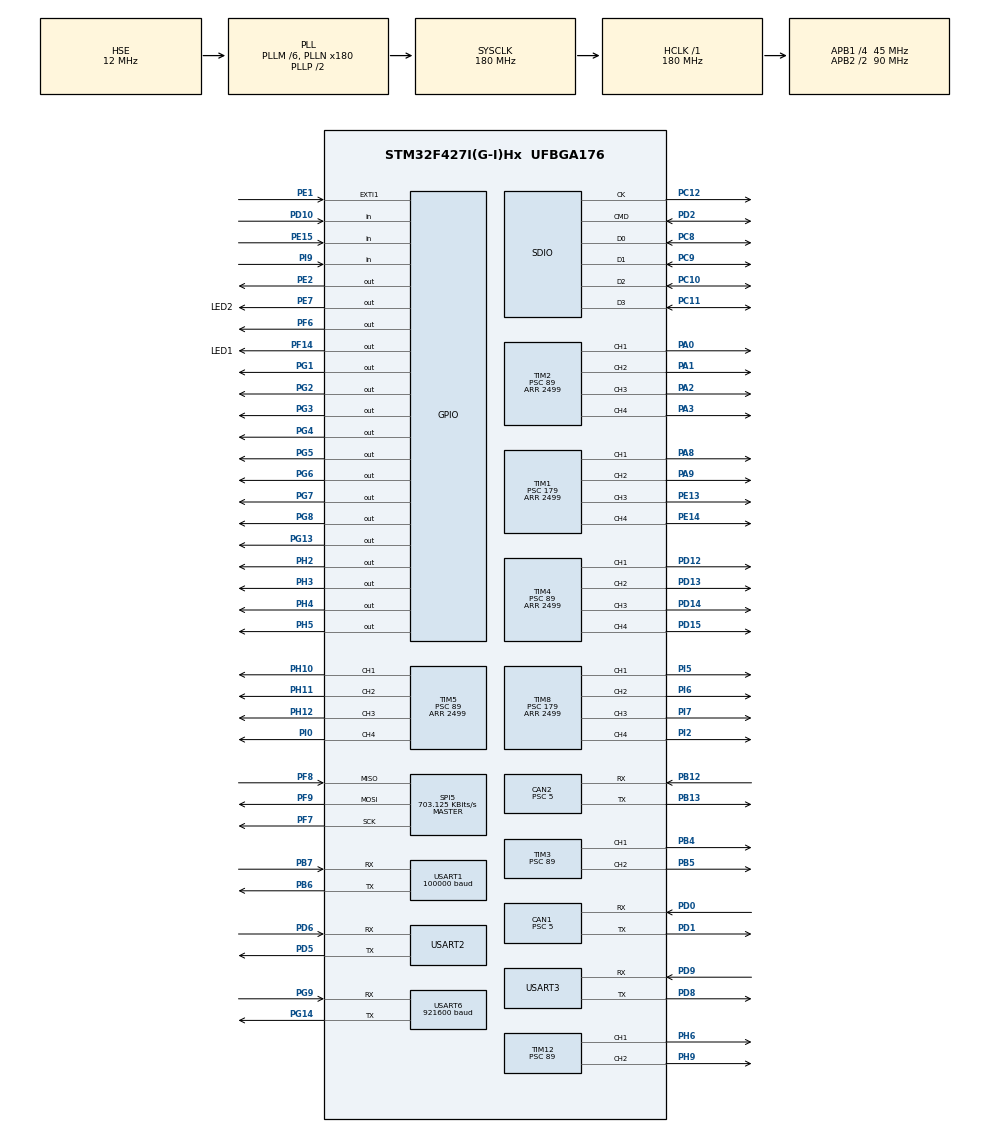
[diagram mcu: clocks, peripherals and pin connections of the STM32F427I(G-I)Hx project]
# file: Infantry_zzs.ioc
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CAN1.ABOM=ENABLE
CAN1.BS1=CAN_BS1_3TQ
CAN1.BS2=CAN_BS2_5TQ
CAN1.CalculateTimeQuantum=111.11111111111111
CAN1.Prescaler=5
CAN2.ABOM=ENABLE
CAN2.BS1=CAN_BS1_3TQ
CAN2.BS2=CAN_BS2_5TQ
CAN2.CalculateTimeQuantum=111.11111111111111
CAN2.Prescaler=5
CAN2.SJW=CAN_SJW_4TQ
Dma.Request0=USART1_RX
Dma.Request1=USART2_RX
Dma.Request2=USART2_TX
Dma.Request3=USART3_RX
Dma.Request4=USART3_TX
Dma.Request5=USART6_RX
Dma.Request6=USART6_TX
Dma.USART1_RX.0.Direction=DMA_PERIPH_TO_MEMORY
Dma.USART1_RX.0.FIFOMode=DMA_FIFOMODE_DISABLE
Dma.USART1_RX.0.Instance=DMA2_Stream2
Dma.USART1_RX.0.MemDataAlignment=DMA_MDATAALIGN_BYTE
Dma.USART1_RX.0.MemInc=DMA_MINC_ENABLE
Dma.USART1_RX.0.Mode=DMA_NORMAL
Dma.USART1_RX.0.PeriphDataAlignment=DMA_PDATAALIGN_BYTE
Dma.USART1_RX.0.PeriphInc=DMA_PINC_DISABLE
Dma.USART1_RX.0.Priority=DMA_PRIORITY_LOW
Dma.USART2_RX.1.Direction=DMA_PERIPH_TO_MEMORY
Dma.USART2_RX.1.FIFOMode=DMA_FIFOMODE_DISABLE
Dma.USART2_RX.1.Instance=DMA1_Stream5
Dma.USART2_RX.1.MemDataAlignment=DMA_MDATAALIGN_BYTE
Dma.USART2_RX.1.MemInc=DMA_MINC_ENABLE
Dma.USART2_RX.1.Mode=DMA_NORMAL
Dma.USART2_RX.1.PeriphDataAlignment=DMA_PDATAALIGN_BYTE
Dma.USART2_RX.1.PeriphInc=DMA_PINC_DISABLE
Dma.USART2_RX.1.Priority=DMA_PRIORITY_LOW
Dma.USART2_TX.2.Direction=DMA_MEMORY_TO_PERIPH
Dma.USART2_TX.2.FIFOMode=DMA_FIFOMODE_DISABLE
Dma.USART2_TX.2.Instance=DMA1_Stream6
Dma.USART2_TX.2.MemDataAlignment=DMA_MDATAALIGN_BYTE
Dma.USART2_TX.2.MemInc=DMA_MINC_ENABLE
Dma.USART2_TX.2.Mode=DMA_NORMAL
Dma.USART2_TX.2.PeriphDataAlignment=DMA_PDATAALIGN_BYTE
Dma.USART2_TX.2.PeriphInc=DMA_PINC_DISABLE
Dma.USART2_TX.2.Priority=DMA_PRIORITY_LOW
Dma.USART3_RX.3.Direction=DMA_PERIPH_TO_MEMORY
Dma.USART3_RX.3.FIFOMode=DMA_FIFOMODE_DISABLE
Dma.USART3_RX.3.Instance=DMA1_Stream1
Dma.USART3_RX.3.MemDataAlignment=DMA_MDATAALIGN_BYTE
Dma.USART3_RX.3.MemInc=DMA_MINC_ENABLE
Dma.USART3_RX.3.Mode=DMA_NORMAL
Dma.USART3_RX.3.PeriphDataAlignment=DMA_PDATAALIGN_BYTE
Dma.USART3_RX.3.PeriphInc=DMA_PINC_DISABLE
Dma.USART3_RX.3.Priority=DMA_PRIORITY_LOW
Dma.USART3_TX.4.Direction=DMA_MEMORY_TO_PERIPH
Dma.USART3_TX.4.FIFOMode=DMA_FIFOMODE_DISABLE
Dma.USART3_TX.4.Instance=DMA1_Stream3
Dma.USART3_TX.4.MemDataAlignment=DMA_MDATAALIGN_BYTE
Dma.USART3_TX.4.MemInc=DMA_MINC_ENABLE
Dma.USART3_TX.4.Mode=DMA_NORMAL
Dma.USART3_TX.4.PeriphDataAlignment=DMA_PDATAALIGN_BYTE
Dma.USART3_TX.4.PeriphInc=DMA_PINC_DISABLE
Dma.USART3_TX.4.Priority=DMA_PRIORITY_LOW
Dma.USART6_RX.5.Direction=DMA_PERIPH_TO_MEMORY
Dma.USART6_RX.5.FIFOMode=DMA_FIFOMODE_DISABLE
Dma.USART6_RX.5.Instance=DMA2_Stream1
Dma.USART6_RX.5.MemDataAlignment=DMA_MDATAALIGN_BYTE
Dma.USART6_RX.5.MemInc=DMA_MINC_ENABLE
Dma.USART6_RX.5.Mode=DMA_NORMAL
Dma.USART6_RX.5.PeriphDataAlignment=DMA_PDATAALIGN_BYTE
Dma.USART6_RX.5.PeriphInc=DMA_PINC_DISABLE
Dma.USART6_RX.5.Priority=DMA_PRIORITY_LOW
Dma.USART6_TX.6.Direction=DMA_MEMORY_TO_PERIPH
Dma.USART6_TX.6.FIFOMode=DMA_FIFOMODE_DISABLE
Dma.USART6_TX.6.Instance=DMA2_Stream6
Dma.USART6_TX.6.MemDataAlignment=DMA_MDATAALIGN_BYTE
Dma.USART6_TX.6.MemInc=DMA_MINC_ENABLE
Dma.USART6_TX.6.Mode=DMA_NORMAL
Dma.USART6_TX.6.PeriphDataAlignment=DMA_PDATAALIGN_BYTE
Dma.USART6_TX.6.PeriphInc=DMA_PINC_DISABLE
Dma.USART6_TX.6.Priority=DMA_PRIORITY_LOW
FREERTOS.INCLUDE_pcTaskGetTaskName=0
FREERTOS.INCLUDE_uxTaskGetStackHighWaterMark=1
FREERTOS.INCLUDE_vTaskDelayUntil=1
FREERTOS.Tasks01=defaultTask,0,128,StartDefaultTask,Default,NULL,Dynamic,NULL,NULL;myTask02,3,256,StartTask02,As weak,NULL,Dynamic,NULL,NULL;myTask03,2,256,StartTask03,As weak,NULL,Dynamic,NULL,NULL;myTask04,1,256,StartTask04,As weak,NULL,Dynamic,NULL,NULL;myTask05,0,256,StartTask05,As weak,NULL,Dynamic,NULL,NULL;myTask06,-1,128,StartTask06,As weak,NULL,Dynamic,NULL,NULL;myTask07,-2,128,StartTask07,As weak,NULL,Dynamic,NULL,NULL;myTask08,-3,128,StartTask08,As weak,NULL,Dynamic,NULL,NULL
FREERTOS.configCHECK_FOR_STACK_OVERFLOW=1
FREERTOS.configTIMER_TASK_STACK_DEPTH=128
FREERTOS.configUSE_TIMERS=1
FREERTOS.configUSE_TRACE_FACILITY=1
Mcu.Family=STM32F4
Mcu.Name=STM32F427I(G-I)Hx
Mcu.Package=UFBGA176
NVIC.CAN1_RX0_IRQn=true\:5\:0\:false\:false\:true\:true\:true
NVIC.CAN1_TX_IRQn=true\:5\:0\:false\:false\:true\:true\:true
NVIC.CAN2_RX0_IRQn=true\:6\:0\:true\:false\:true\:true\:true
NVIC.CAN2_TX_IRQn=true\:6\:0\:true\:false\:true\:true\:true
NVIC.DMA1_Stream1_IRQn=true\:5\:0\:false\:false\:true\:true\:false
NVIC.DMA1_Stream3_IRQn=true\:5\:0\:false\:false\:true\:true\:false
NVIC.DMA1_Stream5_IRQn=true\:5\:0\:false\:false\:true\:true\:false
NVIC.DMA1_Stream6_IRQn=true\:5\:0\:false\:false\:true\:true\:false
NVIC.DMA2_Stream1_IRQn=true\:5\:0\:false\:false\:true\:true\:false
NVIC.DMA2_Stream2_IRQn=true\:5\:0\:false\:false\:true\:true\:false
NVIC.DMA2_Stream6_IRQn=true\:5\:0\:false\:false\:true\:true\:false
NVIC.PriorityGroup=NVIC_PRIORITYGROUP_4
NVIC.SDIO_IRQn=true\:5\:0\:false\:false\:true\:true\:true
NVIC.TIM6_DAC_IRQn=true\:0\:0\:false\:false\:true\:false\:false
NVIC.TimeBase=TIM6_DAC_IRQn
NVIC.TimeBaseIP=TIM6
NVIC.USART1_IRQn=true\:5\:0\:false\:false\:true\:true\:true
NVIC.USART2_IRQn=true\:5\:0\:false\:false\:true\:true\:true
NVIC.USART6_IRQn=true\:5\:0\:false\:false\:true\:true\:true
PA0/WKUP.Signal=S_TIM2_CH1_ETR
PA1.Signal=S_TIM2_CH2
PA13.Mode=Serial_Wire
PA13.Signal=SYS_JTMS-SWDIO
PA14.Mode=Serial_Wire
PA14.Signal=SYS_JTCK-SWCLK
PA2.Signal=S_TIM2_CH3
PA3.Signal=S_TIM2_CH4
PA8.Signal=S_TIM1_CH1
PA9.Signal=S_TIM1_CH2
PB12.Mode=Slave
PB12.Signal=CAN2_RX
PB13.Mode=Slave
PB13.Signal=CAN2_TX
PB4.Signal=S_TIM3_CH1
PB5.Signal=S_TIM3_CH2
PB6.Mode=Asynchronous
PB6.Signal=USART1_TX
PB7.Mode=Asynchronous
PB7.Signal=USART1_RX
PC10.Mode=SD_4_bits_Wide_bus
PC10.Signal=SDIO_D2
PC11.Mode=SD_4_bits_Wide_bus
PC11.Signal=SDIO_D3
PC12.Mode=SD_4_bits_Wide_bus
PC12.Signal=SDIO_CK
PC8.Mode=SD_4_bits_Wide_bus
PC8.Signal=SDIO_D0
PC9.Mode=SD_4_bits_Wide_bus
PC9.Signal=SDIO_D1
PD0.Mode=Master
PD0.Signal=CAN1_RX
PD1.Mode=Master
PD1.Signal=CAN1_TX
PD10.Signal=GPIO_Input
PD12.Signal=S_TIM4_CH1
PD13.Signal=S_TIM4_CH2
PD14.Signal=S_TIM4_CH3
PD15.Signal=S_TIM4_CH4
PD2.Mode=SD_4_bits_Wide_bus
PD2.Signal=SDIO_CMD
PD5.Mode=Asynchronous
PD5.Signal=USART2_TX
PD6.Mode=Asynchronous
PD6.Signal=USART2_RX
PD8.Mode=Asynchronous
PD8.Signal=USART3_TX
PD9.Mode=Asynchronous
PD9.Signal=USART3_RX
PE1.Signal=GPXTI1
PE13.GPIO_ModeDefaultPP=GPIO_MODE_AF_PP
PE13.Signal=S_TIM1_CH3
PE14.Signal=S_TIM1_CH4
PE15.Signal=GPIO_Input
PE2.Signal=GPIO_Output
PE7.GPIO_Label=LED2
PE7.Signal=GPIO_Output
PF14.GPIO_Label=LED1
PF14.Signal=GPIO_Output
PF6.Signal=GPIO_Output
PF7.Mode=Full_Duplex_Master
PF7.Signal=SPI5_SCK
PF8.Mode=Full_Duplex_Master
PF8.Signal=SPI5_MISO
PF9.Mode=Full_Duplex_Master
PF9.Signal=SPI5_MOSI
PG1.GPIO_Speed=GPIO_SPEED_FREQ_HIGH
PG1.PinState=GPIO_PIN_RESET
PG1.Signal=GPIO_Output
PG13.Signal=GPIO_Output
PG14.Mode=Asynchronous
PG14.Signal=USART6_TX
PG2.GPIO_Speed=GPIO_SPEED_FREQ_HIGH
PG2.Signal=GPIO_Output
PG3.GPIO_Speed=GPIO_SPEED_FREQ_HIGH
PG3.Signal=GPIO_Output
PG4.GPIO_Speed=GPIO_SPEED_FREQ_HIGH
PG4.Signal=GPIO_Output
PG5.GPIO_Speed=GPIO_SPEED_FREQ_HIGH
PG5.Signal=GPIO_Output
PG6.GPIO_Speed=GPIO_SPEED_FREQ_HIGH
PG6.Signal=GPIO_Output
PG7.GPIO_Speed=GPIO_SPEED_FREQ_HIGH
PG7.Signal=GPIO_Output
PG8.GPIO_Speed=GPIO_SPEED_FREQ_HIGH
PG8.Signal=GPIO_Output
PG9.Mode=Asynchronous
PG9.Signal=USART6_RX
PH0/OSC_IN.Mode=HSE-External-Oscillator
PH0/OSC_IN.Signal=RCC_OSC_IN
PH1/OSC_OUT.Mode=HSE-External-Oscillator
PH1/OSC_OUT.Signal=RCC_OSC_OUT
PH10.Signal=S_TIM5_CH1
PH11.Signal=S_TIM5_CH2
PH12.Signal=S_TIM5_CH3
PH2.GPIO_ModeDefaultOutputPP=GPIO_MODE_OUTPUT_PP
PH2.GPIO_PuPd=GPIO_PULLUP
PH2.GPIO_Speed=GPIO_SPEED_FREQ_HIGH
PH2.PinState=GPIO_PIN_SET
PH2.Signal=GPIO_Output
PH3.GPIO_PuPd=GPIO_PULLUP
PH3.GPIO_Speed=GPIO_SPEED_FREQ_HIGH
PH3.PinState=GPIO_PIN_SET
PH3.Signal=GPIO_Output
PH4.GPIO_PuPd=GPIO_PULLUP
PH4.GPIO_Speed=GPIO_SPEED_FREQ_HIGH
PH4.PinState=GPIO_PIN_SET
PH4.Signal=GPIO_Output
PH5.GPIO_ModeDefaultOutputPP=GPIO_MODE_OUTPUT_PP
PH5.GPIO_PuPd=GPIO_PULLUP
PH5.GPIO_Speed=GPIO_SPEED_FREQ_HIGH
PH5.PinState=GPIO_PIN_SET
PH5.Signal=GPIO_Output
PH6.Signal=S_TIM12_CH1
PH9.Signal=S_TIM12_CH2
PI0.Signal=S_TIM5_CH4
PI2.Signal=S_TIM8_CH4
PI5.Signal=S_TIM8_CH1
PI6.Signal=S_TIM8_CH2
PI7.Signal=S_TIM8_CH3
PI9.Signal=GPIO_Input
ProjectManager.HeapSize=0x200
ProjectManager.StackSize=0x400
ProjectManager.TargetToolchain=MDK-ARM V5
RCC.48MHZClocksFreq_Value=45000000
RCC.AHBFreq_Value=180000000
RCC.APB1CLKDivider=RCC_HCLK_DIV4
RCC.APB1Freq_Value=45000000
RCC.APB1TimFreq_Value=90000000
RCC.APB2CLKDivider=RCC_HCLK_DIV2
RCC.APB2Freq_Value=90000000
RCC.APB2TimFreq_Value=180000000
RCC.CortexFreq_Value=180000000
RCC.HCLKFreq_Value=180000000
RCC.HSE_VALUE=12000000
RCC.HSI_VALUE=16000000
RCC.LSE_VALUE=32768
RCC.PLLM=6
RCC.PLLN=180
RCC.PLLQ=8
RCC.PLLSourceVirtual=RCC_PLLSOURCE_HSE
RCC.SYSCLKFreq_VALUE=180000000
RCC.SYSCLKSource=RCC_SYSCLKSOURCE_PLLCLK
RCC.VCOOutputFreq_Value=360000000
SH.S_TIM12_CH1.0=TIM12_CH1,PWM Generation1 CH1
SH.S_TIM12_CH2.0=TIM12_CH2,PWM Generation2 CH2
SH.S_TIM1_CH1.0=TIM1_CH1,PWM Generation1 CH1
SH.S_TIM1_CH2.0=TIM1_CH2,PWM Generation2 CH2
SH.S_TIM1_CH3.0=TIM1_CH3,PWM Generation3 CH3
SH.S_TIM1_CH4.0=TIM1_CH4,PWM Generation4 CH4
SH.S_TIM2_CH1_ETR.0=TIM2_CH1,PWM Generation1 CH1
SH.S_TIM2_CH2.0=TIM2_CH2,PWM Generation2 CH2
SH.S_TIM2_CH3.0=TIM2_CH3,PWM Generation3 CH3
SH.S_TIM2_CH4.0=TIM2_CH4,PWM Generation4 CH4
SH.S_TIM3_CH1.0=TIM3_CH1,PWM Generation1 CH1
SH.S_TIM3_CH2.0=TIM3_CH2,PWM Generation2 CH2
SH.S_TIM4_CH1.0=TIM4_CH1,PWM Generation1 CH1
SH.S_TIM4_CH2.0=TIM4_CH2,PWM Generation2 CH2
SH.S_TIM4_CH3.0=TIM4_CH3,PWM Generation3 CH3
SH.S_TIM4_CH4.0=TIM4_CH4,PWM Generation4 CH4
SH.S_TIM5_CH1.0=TIM5_CH1,PWM Generation1 CH1
SH.S_TIM5_CH2.0=TIM5_CH2,PWM Generation2 CH2
SH.S_TIM5_CH3.0=TIM5_CH3,PWM Generation3 CH3
SH.S_TIM5_CH4.0=TIM5_CH4,PWM Generation4 CH4
SH.S_TIM8_CH1.0=TIM8_CH1,PWM Generation1 CH1
SH.S_TIM8_CH2.0=TIM8_CH2,PWM Generation2 CH2
SH.S_TIM8_CH3.0=TIM8_CH3,PWM Generation3 CH3
SH.S_TIM8_CH4.0=TIM8_CH4,PWM Generation4 CH4
SPI5.BaudRatePrescaler=SPI_BAUDRATEPRESCALER_128
SPI5.CalculateBaudRate=703.125 KBits/s
SPI5.Direction=SPI_DIRECTION_2LINES
SPI5.Mode=SPI_MODE_MASTER
SPI5.VirtualType=VM_MASTER
TIM1.Channel-PWM\ Generation1\ CH1=TIM_CHANNEL_1
TIM1.Channel-PWM\ Generation2\ CH2=TIM_CHANNEL_2
TIM1.Channel-PWM\ Generation3\ CH3=TIM_CHANNEL_3
TIM1.Channel-PWM\ Generation4\ CH4=TIM_CHANNEL_4
TIM1.Period=2499
TIM1.Prescaler=179
TIM1.Pulse-PWM\ Generation1\ CH1=1000
TIM1.Pulse-PWM\ Generation2\ CH2=1000
TIM1.Pulse-PWM\ Generation3\ CH3=1000
TIM1.Pulse-PWM\ Generation4\ CH4=1000
TIM12.Channel-PWM\ Generation1\ CH1=TIM_CHANNEL_1
TIM12.Channel-PWM\ Generation2\ CH2=TIM_CHANNEL_2
TIM12.Period=2499
TIM12.Prescaler=89
TIM12.Pulse-PWM\ Generation1\ CH1=1000
TIM12.Pulse-PWM\ Generation2\ CH2=1000
TIM2.Channel-PWM\ Generation1\ CH1=TIM_CHANNEL_1
TIM2.Channel-PWM\ Generation2\ CH2=TIM_CHANNEL_2
TIM2.Channel-PWM\ Generation3\ CH3=TIM_CHANNEL_3
TIM2.Channel-PWM\ Generation4\ CH4=TIM_CHANNEL_4
TIM2.Period=2499
TIM2.Prescaler=89
TIM2.Pulse-PWM\ Generation1\ CH1=1000
TIM2.Pulse-PWM\ Generation2\ CH2=1000
TIM2.Pulse-PWM\ Generation3\ CH3=1000
TIM2.Pulse-PWM\ Generation4\ CH4=1000
TIM3.Channel-PWM\ Generation1\ CH1=TIM_CHANNEL_1
TIM3.Channel-PWM\ Generation2\ CH2=TIM_CHANNEL_2
TIM3.Prescaler=89
TIM4.Channel-PWM\ Generation1\ CH1=TIM_CHANNEL_1
TIM4.Channel-PWM\ Generation2\ CH2=TIM_CHANNEL_2
TIM4.Channel-PWM\ Generation3\ CH3=TIM_CHANNEL_3
TIM4.Channel-PWM\ Generation4\ CH4=TIM_CHANNEL_4
TIM4.Period=2499
TIM4.Prescaler=89
TIM4.Pulse-PWM\ Generation1\ CH1=1000
TIM4.Pulse-PWM\ Generation2\ CH2=1000
TIM4.Pulse-PWM\ Generation3\ CH3=1000
TIM4.Pulse-PWM\ Generation4\ CH4=1000
TIM5.Channel-PWM\ Generation1\ CH1=TIM_CHANNEL_1
TIM5.Channel-PWM\ Generation2\ CH2=TIM_CHANNEL_2
TIM5.Channel-PWM\ Generation3\ CH3=TIM_CHANNEL_3
TIM5.Channel-PWM\ Generation4\ CH4=TIM_CHANNEL_4
TIM5.Period=2499
TIM5.Prescaler=89
TIM5.Pulse-PWM\ Generation1\ CH1=1000
TIM5.Pulse-PWM\ Generation2\ CH2=1000
TIM5.Pulse-PWM\ Generation3\ CH3=1000
TIM5.Pulse-PWM\ Generation4\ CH4=1000
TIM8.Channel-PWM\ Generation1\ CH1=TIM_CHANNEL_1
TIM8.Channel-PWM\ Generation2\ CH2=TIM_CHANNEL_2
TIM8.Channel-PWM\ Generation3\ CH3=TIM_CHANNEL_3
TIM8.Channel-PWM\ Generation4\ CH4=TIM_CHANNEL_4
TIM8.Period=2499
TIM8.Prescaler=179
TIM8.Pulse-PWM\ Generation1\ CH1=1000
TIM8.Pulse-PWM\ Generation2\ CH2=1000
TIM8.Pulse-PWM\ Generation3\ CH3=1000
TIM8.Pulse-PWM\ Generation4\ CH4=1000
USART1.BaudRate=100000
USART1.Parity=PARITY_EVEN
USART1.VirtualMode=VM_ASYNC
USART2.VirtualMode=VM_ASYNC
USART3.VirtualMode=VM_ASYNC
USART6.BaudRate=921600
USART6.VirtualMode=VM_ASYNC
VP_FREERTOS_VS_ENABLE.Mode=Enabled
VP_RTC_VS_RTC_Activate.Mode=RTC_Enabled
VP_RTC_VS_RTC_Calendar.Mode=RTC_Calendar
VP_RTC_VS_RTC_WakeUp_intern.Mode=WakeUp
VP_SYS_VS_tim6.Mode=TIM6
board=custom

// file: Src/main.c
/* USER CODE BEGIN Header */
/**
  ******************************************************************************
  * @file           : main.c
  * @brief          : Main program body
  ******************************************************************************
  * This notice applies to any and all portions of this file
  * that are not between comment pairs USER CODE BEGIN and
  * USER CODE END. Other portions of this file, whether
  * inserted by the user or by software development tools
  * are owned by their respective copyright owners.
  *
  * Copyright (c) 2019 STMicroelectronics International N.V.
  * All rights reserved.
  *
  * Redistribution and use in source and binary forms, with or without
  * modification, are permitted, provided that the following conditions are met:
  *
  * 1. Redistribution of source code must retain the above copyright notice,
  *    this list of conditions and the following disclaimer.
  * 2. Redistributions in binary form must reproduce the above copyright notice,
  *    this list of conditions and the following disclaimer in the documentation
  *    and/or other materials provided with the distribution.
  * 3. Neither the name of STMicroelectronics nor the names of other
  *    contributors to this software may be used to endorse or promote products
  *    derived from this software without specific written permission.
  * 4. This software, including modifications and/or derivative works of this
  *    software, must execute solely and exclusively on microcontroller or
  *    microprocessor devices manufactured by or for STMicroelectronics.
  * 5. Redistribution and use of this software other than as permitted under
  *    this license is void and will automatically terminate your rights under
  *    this license.
  *
  * THIS SOFTWARE IS PROVIDED BY STMICROELECTRONICS AND CONTRIBUTORS "AS IS"
  * AND ANY EXPRESS, IMPLIED OR STATUTORY WARRANTIES, INCLUDING, BUT NOT
  * LIMITED TO, THE IMPLIED WARRANTIES OF MERCHANTABILITY, FITNESS FOR A
  * PARTICULAR PURPOSE AND NON-INFRINGEMENT OF THIRD PARTY INTELLECTUAL PROPERTY
  * RIGHTS ARE DISCLAIMED TO THE FULLEST EXTENT PERMITTED BY LAW. IN NO EVENT
  * SHALL STMICROELECTRONICS OR CONTRIBUTORS BE LIABLE FOR ANY DIRECT, INDIRECT,
  * INCIDENTAL, SPECIAL, EXEMPLARY, OR CONSEQUENTIAL DAMAGES (INCLUDING, BUT NOT
  * LIMITED TO, PROCUREMENT OF SUBSTITUTE GOODS OR SERVICES; LOSS OF USE, DATA,
  * OR PROFITS; OR BUSINESS INTERRUPTION) HOWEVER CAUSED AND ON ANY THEORY OF
  * LIABILITY, WHETHER IN CONTRACT, STRICT LIABILITY, OR TORT (INCLUDING
  * NEGLIGENCE OR OTHERWISE) ARISING IN ANY WAY OUT OF THE USE OF THIS SOFTWARE,
  * EVEN IF ADVISED OF THE POSSIBILITY OF SUCH DAMAGE.
  *
  ******************************************************************************
  */
/* USER CODE END Header */

#include "main.h"
#include "cmsis_os.h"
#include "can.h"
#include "dma.h"
#include "rtc.h"
#include "sdio.h"
#include "spi.h"
#include "tim.h"
#include "usart.h"
#include "gpio.h"

/* USER CODE BEGIN Includes */
#include "BSP_can.h"
#include "BSP_usart.h"
#include "delay.h"
#include "ChassisControl.h"
#include "GimbalControl.h"
#include "ShootControl.h"
#include "MPU6500.h"
/* USER CODE END Includes */

void SystemClock_Config(void);
void MX_FREERTOS_Init(void);

int main(void)
{

  /* MCU Configuration--------------------------------------------------------*/

  /* Reset of all peripherals, Initializes the Flash interface and the Systick. */
  HAL_Init();

  /* Configure the system clock */
  SystemClock_Config();

  /* Initialize all configured peripherals */
  MX_GPIO_Init();
  MX_DMA_Init();
  MX_RTC_Init();
  MX_TIM1_Init();
  MX_TIM2_Init();
  MX_TIM3_Init();
  MX_TIM4_Init();
  MX_TIM5_Init();
  MX_TIM8_Init();
  MX_TIM12_Init();
  MX_CAN1_Init();
  MX_CAN2_Init();
  MX_SDIO_SD_Init();
  MX_SPI5_Init();
  MX_USART1_UART_Init();
  MX_USART2_UART_Init();
  MX_USART3_UART_Init();
  MX_USART6_UART_Init();
  /* USER CODE BEGIN 2 */

	ChassisInit();
	ShootInit();
	GimbalInit();
	PWMInit();

	MPU6500_Init();
	xdelay_ms(6000);
	USART3_Enable();
	USART2_Enable();
	USART1_Enable();
	CAN_Enable();
  /* USER CODE END 2 */

  /* Call init function for freertos objects (in freertos.c) */
  MX_FREERTOS_Init();

  /* Start scheduler */
  osKernelStart();

  /* We should never get here as control is now taken by the scheduler */

  /* Infinite loop */
  while (1)
  {

  }
}

void SystemClock_Config(void)
{
  RCC_OscInitTypeDef RCC_OscInitStruct = {0};
  RCC_ClkInitTypeDef RCC_ClkInitStruct = {0};
  RCC_PeriphCLKInitTypeDef PeriphClkInitStruct = {0};

  /**Configure the main internal regulator output voltage
  */
  __HAL_RCC_PWR_CLK_ENABLE();
  __HAL_PWR_VOLTAGESCALING_CONFIG(PWR_REGULATOR_VOLTAGE_SCALE1);
  /**Initializes the CPU, AHB and APB busses clocks
  */
  RCC_OscInitStruct.OscillatorType = RCC_OSCILLATORTYPE_LSI|RCC_OSCILLATORTYPE_HSE;
  RCC_OscInitStruct.HSEState = RCC_HSE_ON;
  RCC_OscInitStruct.LSIState = RCC_LSI_ON;
  RCC_OscInitStruct.PLL.PLLState = RCC_PLL_ON;
  RCC_OscInitStruct.PLL.PLLSource = RCC_PLLSOURCE_HSE;
  RCC_OscInitStruct.PLL.PLLM = 6;
  RCC_OscInitStruct.PLL.PLLN = 180;
  RCC_OscInitStruct.PLL.PLLP = RCC_PLLP_DIV2;
  RCC_OscInitStruct.PLL.PLLQ = 8;
  if (HAL_RCC_OscConfig(&RCC_OscInitStruct) != HAL_OK)
  {
    Error_Handler();
  }
  /**Activate the Over-Drive mode
  */
  if (HAL_PWREx_EnableOverDrive() != HAL_OK)
  {
    Error_Handler();
  }
  /**Initializes the CPU, AHB and APB busses clocks
  */
  RCC_ClkInitStruct.ClockType = RCC_CLOCKTYPE_HCLK|RCC_CLOCKTYPE_SYSCLK
                              |RCC_CLOCKTYPE_PCLK1|RCC_CLOCKTYPE_PCLK2;
  RCC_ClkInitStruct.SYSCLKSource = RCC_SYSCLKSOURCE_PLLCLK;
  RCC_ClkInitStruct.AHBCLKDivider = RCC_SYSCLK_DIV1;
  RCC_ClkInitStruct.APB1CLKDivider = RCC_HCLK_DIV4;
  RCC_ClkInitStruct.APB2CLKDivider = RCC_HCLK_DIV2;

  if (HAL_RCC_ClockConfig(&RCC_ClkInitStruct, FLASH_LATENCY_5) != HAL_OK)
  {
    Error_Handler();
  }
  PeriphClkInitStruct.PeriphClockSelection = RCC_PERIPHCLK_RTC;
  PeriphClkInitStruct.RTCClockSelection = RCC_RTCCLKSOURCE_LSI;
  if (HAL_RCCEx_PeriphCLKConfig(&PeriphClkInitStruct) != HAL_OK)
  {
    Error_Handler();
  }
}

void HAL_TIM_PeriodElapsedCallback(TIM_HandleTypeDef *htim)
{
  if (htim->Instance == TIM6) {
    HAL_IncTick();
  }
}

void Error_Handler(void)
{
}

/************************ (C) COPYRIGHT STMicroelectronics *****END OF FILE****/

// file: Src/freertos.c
/* USER CODE BEGIN Header */
/**
  ******************************************************************************
  * File Name          : freertos.c
  * Description        : Code for freertos applications
  ******************************************************************************
  * This notice applies to any and all portions of this file
  * that are not between comment pairs USER CODE BEGIN and
  * USER CODE END. Other portions of this file, whether
  * inserted by the user or by software development tools
  * are owned by their respective copyright owners.
  *
  * Copyright (c) 2019 STMicroelectronics International N.V.
  * All rights reserved.
  *
  * Redistribution and use in source and binary forms, with or without
  * modification, are permitted, provided that the following conditions are met:
  *
  * 1. Redistribution of source code must retain the above copyright notice,
  *    this list of conditions and the following disclaimer.
  * 2. Redistributions in binary form must reproduce the above copyright notice,
  *    this list of conditions and the following disclaimer in the documentation
  *    and/or other materials provided with the distribution.
  * 3. Neither the name of STMicroelectronics nor the names of other
  *    contributors to this software may be used to endorse or promote products
  *    derived from this software without specific written permission.
  * 4. This software, including modifications and/or derivative works of this
  *    software, must execute solely and exclusively on microcontroller or
  *    microprocessor devices manufactured by or for STMicroelectronics.
  * 5. Redistribution and use of this software other than as permitted under
  *    this license is void and will automatically terminate your rights under
  *    this license.
  *
  * THIS SOFTWARE IS PROVIDED BY STMICROELECTRONICS AND CONTRIBUTORS "AS IS"
  * AND ANY EXPRESS, IMPLIED OR STATUTORY WARRANTIES, INCLUDING, BUT NOT
  * LIMITED TO, THE IMPLIED WARRANTIES OF MERCHANTABILITY, FITNESS FOR A
  * PARTICULAR PURPOSE AND NON-INFRINGEMENT OF THIRD PARTY INTELLECTUAL PROPERTY
  * RIGHTS ARE DISCLAIMED TO THE FULLEST EXTENT PERMITTED BY LAW. IN NO EVENT
  * SHALL STMICROELECTRONICS OR CONTRIBUTORS BE LIABLE FOR ANY DIRECT, INDIRECT,
  * INCIDENTAL, SPECIAL, EXEMPLARY, OR CONSEQUENTIAL DAMAGES (INCLUDING, BUT NOT
  * LIMITED TO, PROCUREMENT OF SUBSTITUTE GOODS OR SERVICES; LOSS OF USE, DATA,
  * OR PROFITS; OR BUSINESS INTERRUPTION) HOWEVER CAUSED AND ON ANY THEORY OF
  * LIABILITY, WHETHER IN CONTRACT, STRICT LIABILITY, OR TORT (INCLUDING
  * NEGLIGENCE OR OTHERWISE) ARISING IN ANY WAY OUT OF THE USE OF THIS SOFTWARE,
  * EVEN IF ADVISED OF THE POSSIBILITY OF SUCH DAMAGE.
  *
  ******************************************************************************
  */
/* USER CODE END Header */

#include "FreeRTOS.h"
#include "task.h"
#include "main.h"
#include "cmsis_os.h"

osThreadId defaultTaskHandle;
osThreadId myTask02Handle;
osThreadId myTask03Handle;
osThreadId myTask04Handle;
osThreadId myTask05Handle;
osThreadId myTask06Handle;
osThreadId myTask07Handle;
osThreadId myTask08Handle;

void StartDefaultTask(void const * argument);
void StartTask02(void const * argument);
void StartTask03(void const * argument);
void StartTask04(void const * argument);
void StartTask05(void const * argument);
void StartTask06(void const * argument);
void StartTask07(void const * argument);
void StartTask08(void const * argument);

void MX_FREERTOS_Init(void); /* (MISRA C 2004 rule 8.1) */

/* Hook prototypes */
void vApplicationStackOverflowHook(xTaskHandle xTask, signed char *pcTaskName);

/* USER CODE BEGIN 4 */
__weak void vApplicationStackOverflowHook(xTaskHandle xTask, signed char *pcTaskName)
{
   /* Run time stack overflow checking is performed if
   configCHECK_FOR_STACK_OVERFLOW is defined to 1 or 2. This hook function is
   called if a stack overflow is detected. */
}
/* USER CODE END 4 */

void MX_FREERTOS_Init(void) {

  /* Create the thread(s) */
  /* definition and creation of defaultTask */
  osThreadDef(defaultTask, StartDefaultTask, osPriorityNormal, 0, 128);
  defaultTaskHandle = osThreadCreate(osThread(defaultTask), NULL);

  /* definition and creation of myTask02 */
  osThreadDef(myTask02, StartTask02, osPriorityRealtime, 0, 256);
  myTask02Handle = osThreadCreate(osThread(myTask02), NULL);

  /* definition and creation of myTask03 */
  osThreadDef(myTask03, StartTask03, osPriorityHigh, 0, 256);
  myTask03Handle = osThreadCreate(osThread(myTask03), NULL);

  /* definition and creation of myTask04 */
  osThreadDef(myTask04, StartTask04, osPriorityAboveNormal, 0, 256);
  myTask04Handle = osThreadCreate(osThread(myTask04), NULL);

  /* definition and creation of myTask05 */
  osThreadDef(myTask05, StartTask05, osPriorityNormal, 0, 256);
  myTask05Handle = osThreadCreate(osThread(myTask05), NULL);

  /* definition and creation of myTask06 */
  osThreadDef(myTask06, StartTask06, osPriorityBelowNormal, 0, 128);
  myTask06Handle = osThreadCreate(osThread(myTask06), NULL);

  /* definition and creation of myTask07 */
  osThreadDef(myTask07, StartTask07, osPriorityLow, 0, 128);
  myTask07Handle = osThreadCreate(osThread(myTask07), NULL);

  /* definition and creation of myTask08 */
  osThreadDef(myTask08, StartTask08, osPriorityIdle, 0, 128);
  myTask08Handle = osThreadCreate(osThread(myTask08), NULL);

}

void StartDefaultTask(void const * argument)
{

  for(;;)
  {
    osDelay(1);
  }
}

__weak void StartTask02(void const * argument)
{
  for(;;)
  {
    osDelay(1);
  }
}

__weak void StartTask03(void const * argument)
{
  for(;;)
  {
    osDelay(1);
  }
}

__weak void StartTask04(void const * argument)
{
  for(;;)
  {
    osDelay(1);
  }
}

__weak void StartTask05(void const * argument)
{
  for(;;)
  {
    osDelay(1);
  }
}

__weak void StartTask06(void const * argument)
{
  for(;;)
  {
    osDelay(1);
  }
}

__weak void StartTask07(void const * argument)
{
  for(;;)
  {
    osDelay(1);
  }
}

__weak void StartTask08(void const * argument)
{
  for(;;)
  {
    osDelay(1);
  }
}

/************************ (C) COPYRIGHT STMicroelectronics *****END OF FILE****/
